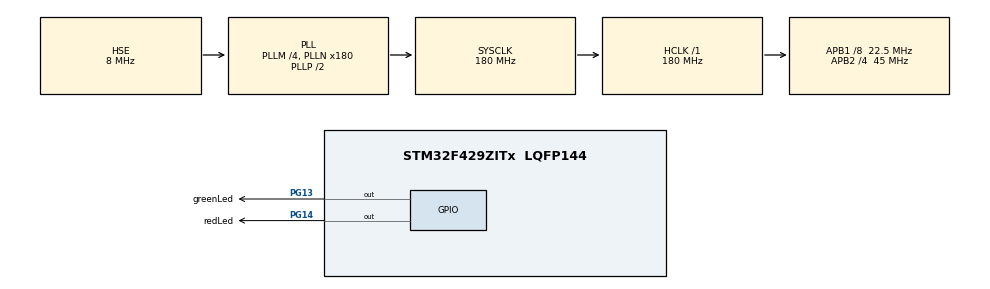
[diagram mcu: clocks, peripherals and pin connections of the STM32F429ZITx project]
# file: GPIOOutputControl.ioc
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FREERTOS.Tasks01=toggleRedLed,1,64,redLedTask,Default,NULL,Dynamic,NULL,NULL;toggleGreenLed,0,64,greenLedTask,Default,NULL,Dynamic,NULL,NULL
FREERTOS.configMINIMAL_STACK_SIZE=64
FREERTOS.configUSE_NEWLIB_REENTRANT=1
Mcu.Family=STM32F4
Mcu.Name=STM32F429ZITx
Mcu.Package=LQFP144
NVIC.PriorityGroup=NVIC_PRIORITYGROUP_4
NVIC.TIM1_UP_TIM10_IRQn=true\:15\:0\:false\:false\:true\:false\:false\:true\:true
NVIC.TimeBase=TIM1_UP_TIM10_IRQn
NVIC.TimeBaseIP=TIM1
PA13.Mode=Serial_Wire
PA13.Signal=SYS_JTMS-SWDIO
PA14.Mode=Serial_Wire
PA14.Signal=SYS_JTCK-SWCLK
PG13.GPIO_Label=greenLed
PG13.GPIO_PuPd=GPIO_PULLDOWN
PG13.Signal=GPIO_Output
PG14.GPIO_Label=redLed
PG14.GPIO_PuPd=GPIO_PULLDOWN
PG14.Signal=GPIO_Output
PH0/OSC_IN.Mode=HSE-External-Oscillator
PH0/OSC_IN.Signal=RCC_OSC_IN
PH1/OSC_OUT.Mode=HSE-External-Oscillator
PH1/OSC_OUT.Signal=RCC_OSC_OUT
ProjectManager.HeapSize=0x200
ProjectManager.StackSize=0x400
ProjectManager.TargetToolchain=STM32CubeIDE
RCC.48MHZClocksFreq_Value=51428571.428571425
RCC.AHBFreq_Value=180000000
RCC.APB1CLKDivider=RCC_HCLK_DIV8
RCC.APB1Freq_Value=22500000
RCC.APB1TimFreq_Value=45000000
RCC.APB2CLKDivider=RCC_HCLK_DIV4
RCC.APB2Freq_Value=45000000
RCC.APB2TimFreq_Value=90000000
RCC.CortexFreq_Value=180000000
RCC.HCLKFreq_Value=180000000
RCC.HSE_VALUE=8000000
RCC.HSI_VALUE=16000000
RCC.LSE_VALUE=32768
RCC.PLLM=4
RCC.PLLN=180
RCC.PLLQ=7
RCC.PLLSourceVirtual=RCC_PLLSOURCE_HSE
RCC.SYSCLKFreq_VALUE=180000000
RCC.SYSCLKSource=RCC_SYSCLKSOURCE_PLLCLK
RCC.VCOOutputFreq_Value=360000000
VP_FREERTOS_VS_CMSIS_V1.Mode=CMSIS_V1
VP_SYS_VS_tim1.Mode=TIM1
board=STM32F429I-DISC1

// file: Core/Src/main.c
/* USER CODE BEGIN Header */
/**
  ******************************************************************************
  * @file           : main.c
  * @brief          : Main program body
  ******************************************************************************
  * @attention
  *
  * Copyright (c) 2025 STMicroelectronics.
  * All rights reserved.
  *
  * This software is licensed under terms that can be found in the LICENSE file
  * in the root directory of this software component.
  * If no LICENSE file comes with this software, it is provided AS-IS.
  *
  ******************************************************************************
  */
/* USER CODE END Header */
#include "main.h"
#include "cmsis_os.h"

/* USER CODE BEGIN PD */
#define ledPort GPIOG
#define greenLedPin GPIO_PIN_13
#define redLedPin GPIO_PIN_14
/* USER CODE END PD */

osThreadId toggleRedLedHandle;
osThreadId toggleGreenLedHandle;

void SystemClock_Config(void);
static void MX_GPIO_Init(void);
void redLedTask(void const * argument);
void greenLedTask(void const * argument);

int main(void)
{

  /* MCU Configuration--------------------------------------------------------*/

  /* Reset of all peripherals, Initializes the Flash interface and the Systick. */
  HAL_Init();

  /* Configure the system clock */
  SystemClock_Config();

  /* Initialize all configured peripherals */
  MX_GPIO_Init();

  /* Create the thread(s) */
  /* definition and creation of toggleRedLed */
  osThreadDef(toggleRedLed, redLedTask, osPriorityAboveNormal, 1, 64);
  toggleRedLedHandle = osThreadCreate(osThread(toggleRedLed), NULL);

  /* definition and creation of toggleGreenLed */
  osThreadDef(toggleGreenLed, greenLedTask, osPriorityNormal, 1, 64);
  toggleGreenLedHandle = osThreadCreate(osThread(toggleGreenLed), NULL);

  /* Start scheduler */
  osKernelStart();

  /* We should never get here as control is now taken by the scheduler */

  /* Infinite loop */
  while (1)
  {

  }
}

void SystemClock_Config(void)
{
  RCC_OscInitTypeDef RCC_OscInitStruct = {0};
  RCC_ClkInitTypeDef RCC_ClkInitStruct = {0};

  /** Configure the main internal regulator output voltage
  */
  __HAL_RCC_PWR_CLK_ENABLE();
  __HAL_PWR_VOLTAGESCALING_CONFIG(PWR_REGULATOR_VOLTAGE_SCALE1);

  /** Initializes the RCC Oscillators according to the specified parameters
  * in the RCC_OscInitTypeDef structure.
  */
  RCC_OscInitStruct.OscillatorType = RCC_OSCILLATORTYPE_HSE;
  RCC_OscInitStruct.HSEState = RCC_HSE_ON;
  RCC_OscInitStruct.PLL.PLLState = RCC_PLL_ON;
  RCC_OscInitStruct.PLL.PLLSource = RCC_PLLSOURCE_HSE;
  RCC_OscInitStruct.PLL.PLLM = 4;
  RCC_OscInitStruct.PLL.PLLN = 180;
  RCC_OscInitStruct.PLL.PLLP = RCC_PLLP_DIV2;
  RCC_OscInitStruct.PLL.PLLQ = 7;
  if (HAL_RCC_OscConfig(&RCC_OscInitStruct) != HAL_OK)
  {
    Error_Handler();
  }

  /** Activate the Over-Drive mode
  */
  if (HAL_PWREx_EnableOverDrive() != HAL_OK)
  {
    Error_Handler();
  }

  /** Initializes the CPU, AHB and APB buses clocks
  */
  RCC_ClkInitStruct.ClockType = RCC_CLOCKTYPE_HCLK|RCC_CLOCKTYPE_SYSCLK
                              |RCC_CLOCKTYPE_PCLK1|RCC_CLOCKTYPE_PCLK2;
  RCC_ClkInitStruct.SYSCLKSource = RCC_SYSCLKSOURCE_PLLCLK;
  RCC_ClkInitStruct.AHBCLKDivider = RCC_SYSCLK_DIV1;
  RCC_ClkInitStruct.APB1CLKDivider = RCC_HCLK_DIV8;
  RCC_ClkInitStruct.APB2CLKDivider = RCC_HCLK_DIV4;

  if (HAL_RCC_ClockConfig(&RCC_ClkInitStruct, FLASH_LATENCY_5) != HAL_OK)
  {
    Error_Handler();
  }
}

static void MX_GPIO_Init(void)
{
  GPIO_InitTypeDef GPIO_InitStruct = {0};

  /* GPIO Ports Clock Enable */
  __HAL_RCC_GPIOH_CLK_ENABLE();
  __HAL_RCC_GPIOA_CLK_ENABLE();
  __HAL_RCC_GPIOG_CLK_ENABLE();

  /*Configure GPIO pin Output Level */
  HAL_GPIO_WritePin(GPIOG, greenLed_Pin|redLed_Pin, GPIO_PIN_RESET);

  /*Configure GPIO pins : greenLed_Pin redLed_Pin */
  GPIO_InitStruct.Pin = greenLed_Pin|redLed_Pin;
  GPIO_InitStruct.Mode = GPIO_MODE_OUTPUT_PP;
  GPIO_InitStruct.Pull = GPIO_PULLDOWN;
  GPIO_InitStruct.Speed = GPIO_SPEED_FREQ_LOW;
  HAL_GPIO_Init(GPIOG, &GPIO_InitStruct);

}

void redLedTask(void const * argument)
{
  /* USER CODE BEGIN 5 */
  /* Infinite loop */
  for(;;)
  {
	  HAL_GPIO_TogglePin(ledPort, redLedPin);
	  osDelay(1000);
  }
  /* USER CODE END 5 */
}

void greenLedTask(void const * argument)
{
  /* USER CODE BEGIN greenLedTask */
  /* Infinite loop */
  for(;;)
  {
	  HAL_GPIO_TogglePin(ledPort, greenLedPin);
	  osDelay(2000);
  }
  /* USER CODE END greenLedTask */
}

void HAL_TIM_PeriodElapsedCallback(TIM_HandleTypeDef *htim)
{
  if (htim->Instance == TIM1) {
    HAL_IncTick();
  }
}

void Error_Handler(void)
{
  __disable_irq();
  while (1)
  {
  }
}
